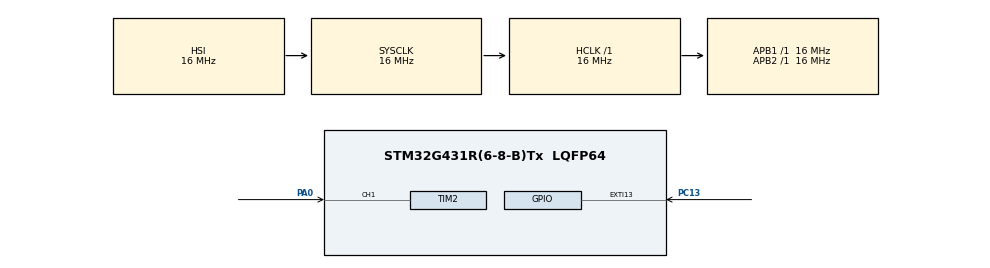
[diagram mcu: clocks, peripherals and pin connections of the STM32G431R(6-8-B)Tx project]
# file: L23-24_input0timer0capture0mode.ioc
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Mcu.Family=STM32G4
Mcu.Name=STM32G431R(6-8-B)Tx
Mcu.Package=LQFP64
NVIC.EXTI15_10_IRQn=true\:0\:0\:false\:false\:true\:true\:true\:true
NVIC.PriorityGroup=NVIC_PRIORITYGROUP_4
NVIC.TIM2_IRQn=true\:0\:0\:false\:false\:true\:true\:true\:true
PA0.Signal=S_TIM2_CH1
PC13.Signal=GPXTI13
ProjectManager.HeapSize=0x200
ProjectManager.StackSize=0x400
ProjectManager.TargetToolchain=STM32CubeIDE
RCC.ADC12Freq_Value=16000000
RCC.AHBFreq_Value=16000000
RCC.APB1Freq_Value=16000000
RCC.APB1TimFreq_Value=16000000
RCC.APB2Freq_Value=16000000
RCC.APB2TimFreq_Value=16000000
RCC.CortexFreq_Value=16000000
RCC.EXTERNAL_CLOCK_VALUE=12288000
RCC.HCLKFreq_Value=16000000
RCC.HSE_VALUE=24000000
RCC.HSI48_VALUE=48000000
RCC.HSI_VALUE=16000000
RCC.LSE_VALUE=32768
RCC.RTCClockSelection=RCC_RTCCLKSOURCE_LSE
RCC.SYSCLKFreq_VALUE=16000000
RCC.USBFreq_Value=64000000
RCC.VCOOutputFreq_Value=128000000
SH.S_TIM2_CH1.0=TIM2_CH1,Input_Capture1_from_TI1
TIM2.Channel-Input_Capture1_from_TI1=TIM_CHANNEL_1
TIM2.PeriodNoDither=65535
TIM2.Prescaler=15999
board=NUCLEO-G431RB

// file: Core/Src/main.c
/* USER CODE BEGIN Header */
/**
  ******************************************************************************
  * @file           : main.c
  * @brief          : Main program body
  ******************************************************************************
  * @attention
  *
  * Copyright (c) 2024 STMicroelectronics.
  * All rights reserved.
  *
  * This software is licensed under terms that can be found in the LICENSE file
  * in the root directory of this software component.
  * If no LICENSE file comes with this software, it is provided AS-IS.
  *
  ******************************************************************************
  */
/* USER CODE END Header */
#include "main.h"

/* USER CODE BEGIN PTD */
extern volatile uint32_t counter, capture;
/* USER CODE END PTD */

TIM_HandleTypeDef htim2;

void SystemClock_Config(void);
static void MX_GPIO_Init(void);
static void MX_TIM2_Init(void);

int main(void)
{

  /* MCU Configuration--------------------------------------------------------*/

  /* Reset of all peripherals, Initializes the Flash interface and the Systick. */
  HAL_Init();

  /* Configure the system clock */
  SystemClock_Config();

  /* Initialize all configured peripherals */
  MX_GPIO_Init();
  MX_TIM2_Init();
  /* USER CODE BEGIN 2 */
  HAL_TIM_IC_Start_IT(&htim2,TIM_CHANNEL_1);
  /* USER CODE END 2 */

  /* Infinite loop */
  /* USER CODE BEGIN WHILE */
  while (1)
  {
	 counter = __HAL_TIM_GetCounter(&htim2);
    /* USER CODE END WHILE */

  }
}

void SystemClock_Config(void)
{
  RCC_OscInitTypeDef RCC_OscInitStruct = {0};
  RCC_ClkInitTypeDef RCC_ClkInitStruct = {0};

  /** Configure the main internal regulator output voltage
  */
  HAL_PWREx_ControlVoltageScaling(PWR_REGULATOR_VOLTAGE_SCALE1);

  /** Initializes the RCC Oscillators according to the specified parameters
  * in the RCC_OscInitTypeDef structure.
  */
  RCC_OscInitStruct.OscillatorType = RCC_OSCILLATORTYPE_HSI;
  RCC_OscInitStruct.HSIState = RCC_HSI_ON;
  RCC_OscInitStruct.HSICalibrationValue = RCC_HSICALIBRATION_DEFAULT;
  RCC_OscInitStruct.PLL.PLLState = RCC_PLL_NONE;
  if (HAL_RCC_OscConfig(&RCC_OscInitStruct) != HAL_OK)
  {
    Error_Handler();
  }

  /** Initializes the CPU, AHB and APB buses clocks
  */
  RCC_ClkInitStruct.ClockType = RCC_CLOCKTYPE_HCLK|RCC_CLOCKTYPE_SYSCLK
                              |RCC_CLOCKTYPE_PCLK1|RCC_CLOCKTYPE_PCLK2;
  RCC_ClkInitStruct.SYSCLKSource = RCC_SYSCLKSOURCE_HSI;
  RCC_ClkInitStruct.AHBCLKDivider = RCC_SYSCLK_DIV1;
  RCC_ClkInitStruct.APB1CLKDivider = RCC_HCLK_DIV1;
  RCC_ClkInitStruct.APB2CLKDivider = RCC_HCLK_DIV1;

  if (HAL_RCC_ClockConfig(&RCC_ClkInitStruct, FLASH_LATENCY_0) != HAL_OK)
  {
    Error_Handler();
  }
}

static void MX_TIM2_Init(void)
{

  TIM_MasterConfigTypeDef sMasterConfig = {0};
  TIM_IC_InitTypeDef sConfigIC = {0};

  htim2.Instance = TIM2;
  htim2.Init.Prescaler = 15999;
  htim2.Init.CounterMode = TIM_COUNTERMODE_UP;
  htim2.Init.Period = 65535;
  htim2.Init.ClockDivision = TIM_CLOCKDIVISION_DIV1;
  htim2.Init.AutoReloadPreload = TIM_AUTORELOAD_PRELOAD_DISABLE;
  if (HAL_TIM_IC_Init(&htim2) != HAL_OK)
  {
    Error_Handler();
  }
  sMasterConfig.MasterOutputTrigger = TIM_TRGO_RESET;
  sMasterConfig.MasterSlaveMode = TIM_MASTERSLAVEMODE_DISABLE;
  if (HAL_TIMEx_MasterConfigSynchronization(&htim2, &sMasterConfig) != HAL_OK)
  {
    Error_Handler();
  }
  sConfigIC.ICPolarity = TIM_INPUTCHANNELPOLARITY_RISING;
  sConfigIC.ICSelection = TIM_ICSELECTION_DIRECTTI;
  sConfigIC.ICPrescaler = TIM_ICPSC_DIV1;
  sConfigIC.ICFilter = 0;
  if (HAL_TIM_IC_ConfigChannel(&htim2, &sConfigIC, TIM_CHANNEL_1) != HAL_OK)
  {
    Error_Handler();
  }

}

static void MX_GPIO_Init(void)
{
  GPIO_InitTypeDef GPIO_InitStruct = {0};

  /* GPIO Ports Clock Enable */
  __HAL_RCC_GPIOC_CLK_ENABLE();
  __HAL_RCC_GPIOA_CLK_ENABLE();

  /*Configure GPIO pin : PC13 */
  GPIO_InitStruct.Pin = GPIO_PIN_13;
  GPIO_InitStruct.Mode = GPIO_MODE_IT_RISING;
  GPIO_InitStruct.Pull = GPIO_NOPULL;
  HAL_GPIO_Init(GPIOC, &GPIO_InitStruct);

  /* EXTI interrupt init*/
  HAL_NVIC_SetPriority(EXTI15_10_IRQn, 2, 0);
  HAL_NVIC_EnableIRQ(EXTI15_10_IRQn);

}

void Error_Handler(void)
{
  __disable_irq();
  while (1)
  {
  }
}
